VERSION "Created by Jacob Geigle"

NS_ :

BS_:

BU_:

BO_ 550 EDL: 4 FC
 SG_ cmd_A : 24|8@1+ (1,0) [0|255] "" FC

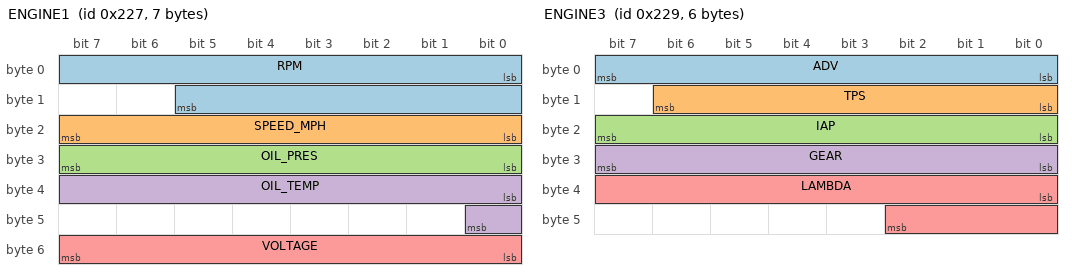
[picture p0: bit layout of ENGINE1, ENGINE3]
BO_ 551 ENGINE1: 7 EDL
 SG_ RPM : 0|14@1+ (1,0) [0|65535] "rpm" FC
 SG_ SPEED_MPH : 16|8@1+ (1,0) [0|255] "MPH" FC
 SG_ OIL_PRES : 24|8@1+ (1,0) [0|255] "psi" FC
 SG_ OIL_TEMP : 32|9@1+ (1,-50) [-50|450] "F" FC
 SG_ VOLTAGE : 48|8@1+ (0.1,0) [0|25.5] "V" FC

CM_ BO_ 551 "EDL Engine Frame 1";
CM_ SG_ 551 RPM "RPM";
CM_ SG_ 551 SPEED_MPH "Speed (MPH)";
CM_ SG_ 551 OIL_PRES "Engine oil pressure (psi)";
CM_ SG_ 551 OIL_TEMP "Engine oil temp (Fahrenheit)";
CM_ SG_ 551 VOLTAGE "System Voltage (0.1 V)";

BO_ 552 ENGINE2: 6 EDL
 SG_ ODO : 0|24@1+ (0.1,0) [0|1677721.0] "km" FC
 SG_ TRIP : 24|20@1+ (0.1,0) [0|104857.0] "km" FC

CM_ BO_ 552 "EDL Engine Frame 2";
CM_ SG_ 552 ODO "Odometer (0.1 km)";
CM_ SG_ 552 TRIP "Tripmeter (0.1 km)";

BO_ 553 ENGINE3: 6 EDL
 SG_ ADV : 0|8@1+ (1,0) [0|255] "deg" FC
 SG_ TPS : 8|7@1+ (1,0) [0|100] "%" FC
 SG_ IAP : 16|8@1+ (1,0) [0|255] "kpa" FC
 SG_ GEAR : 24|8@1+ (1,0) [0|255] "" FC
 SG_ LAMBDA : 32|11@1+ (0.001,0) [0|2.048] "" FC

CM_ BO_ 553 "EDL Engine Frame 3";
CM_ SG_ 553 ADV "Ignition advance";
CM_ SG_ 553 TPS "Throttle position (%)";
CM_ SG_ 553 IAP "Intake absolute pressure (kpa)";
CM_ SG_ 553 GEAR "Numeric gear, 0=N";
CM_ SG_ 553 LAMBDA "Lambda";
